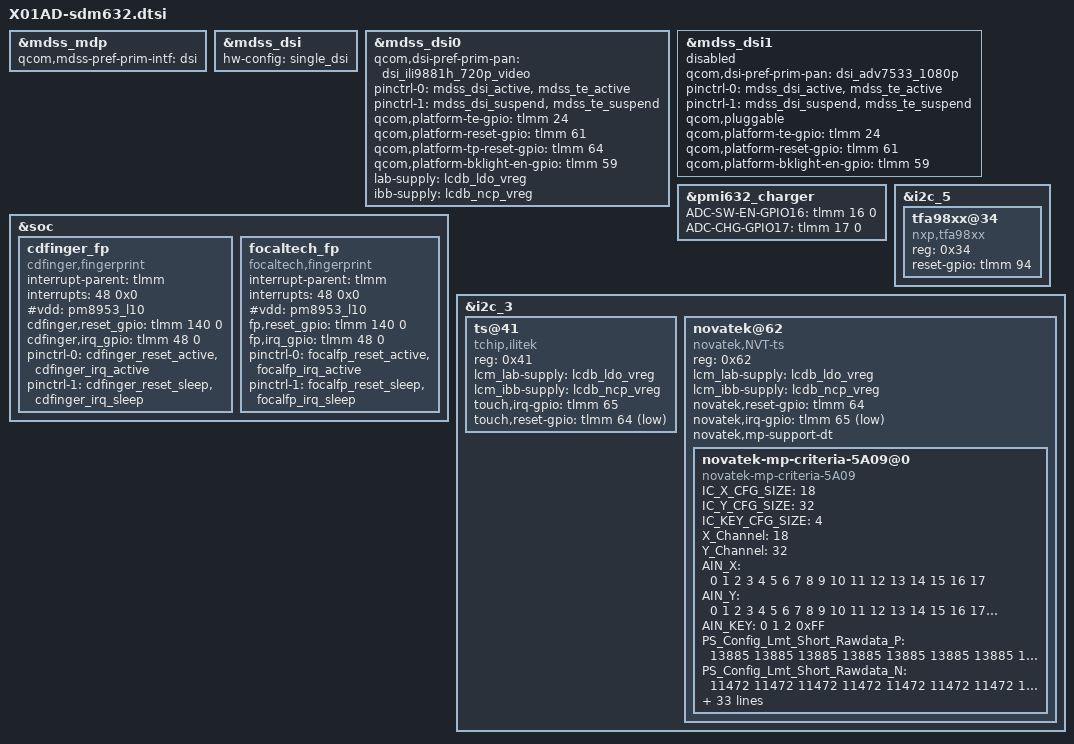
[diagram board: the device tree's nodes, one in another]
/*
 * Copyright (c) 2018, The Linux Foundation. All rights reserved.
 *
 * This program is free software; you can redistribute it and/or modify
 * it under the terms of the GNU General Public License version 2 and
 * only version 2 as published by the Free Software Foundation.
 *
 * This program is distributed in the hope that it will be useful,
 * but WITHOUT ANY WARRANTY; without even the implied warranty of
 * MERCHANTABILITY or FITNESS FOR A PARTICULAR PURPOSE.  See the
 * GNU General Public License for more details.
 */

#include "display/dsi-panel-ili9881h-720p-video.dtsi"
#include "display/dsi-panel-inx6301-720p-video.dtsi"

&mdss_mdp {
	qcom,mdss-pref-prim-intf = "dsi";
};

&mdss_dsi {
	hw-config = "single_dsi";
};

&mdss_dsi0 {
	qcom,dsi-pref-prim-pan = <&dsi_ili9881h_720p_video>;
	pinctrl-names = "mdss_default", "mdss_sleep";
	pinctrl-0 = <&mdss_dsi_active &mdss_te_active>;
	pinctrl-1 = <&mdss_dsi_suspend &mdss_te_suspend>;

	qcom,platform-te-gpio = <&tlmm 24 0>;
	qcom,platform-reset-gpio = <&tlmm 61 0>;
	qcom,platform-tp-reset-gpio = <&tlmm 64 0>;
	qcom,platform-bklight-en-gpio = <&tlmm 59 0>;

	lab-supply = <&lcdb_ldo_vreg>;
	ibb-supply = <&lcdb_ncp_vreg>;
};

&mdss_dsi1 {
	status = "disabled";
	qcom,dsi-pref-prim-pan = <&dsi_adv7533_1080p>;
	pinctrl-names = "mdss_default", "mdss_sleep";
	pinctrl-0 = <&mdss_dsi_active &mdss_te_active>;
	pinctrl-1 = <&mdss_dsi_suspend &mdss_te_suspend>;

	qcom,pluggable;
	qcom,platform-te-gpio = <&tlmm 24 0>;
	qcom,platform-reset-gpio = <&tlmm 61 0>;
	qcom,platform-bklight-en-gpio = <&tlmm 59 0>;
};

&soc {

   cdfinger_fp {
           compatible = "cdfinger,fingerprint";
           interrupt-parent = <&tlmm>;
           interrupts = <48 0x0>;
           #vdd = <&pm8953_l10>;
           cdfinger,reset_gpio = <&tlmm 140 0>;
           cdfinger,irq_gpio = <&tlmm 48 0>;

           pinctrl-names = "cdfinger_active","cdfinger_sleep";
           pinctrl-0 = <&cdfinger_reset_active &cdfinger_irq_active>;
           pinctrl-1 = <&cdfinger_reset_sleep &cdfinger_irq_sleep>;
   };

   focaltech_fp {
           compatible = "focaltech,fingerprint";
           interrupt-parent = <&tlmm>;
           interrupts = <48 0x0>;
           #vdd = <&pm8953_l10>;
           fp,reset_gpio = <&tlmm 140 0>;
           fp,irq_gpio = <&tlmm 48 0>;

           pinctrl-names = "focalfp_active","focalfp_sleep";
           pinctrl-0 = <&focalfp_reset_active &focalfp_irq_active>;
           pinctrl-1 = <&focalfp_reset_sleep &focalfp_irq_sleep>;
   };
};

&pmi632_charger {
       ADC-SW-EN-GPIO16 = <&tlmm 16 0>;
       ADC-CHG-GPIO17 = <&tlmm 17 0>;
};

&i2c_5 {
	status = "okay";
	tfa98xx@34 {
		compatible = "nxp,tfa98xx";
		reg = <0x34>;
		reset-gpio =<&tlmm 94 0>;
	};
};

&i2c_3 {
	status = "ok";
		ts@41 {
		status = "okay";
		compatible = "tchip,ilitek";
		reg = <0x41>;
		lcm_lab-supply = <&lcdb_ldo_vreg>;
		lcm_ibb-supply = <&lcdb_ncp_vreg>;
		touch,irq-gpio = <&tlmm 65 IRQ_TYPE_NONE>;
		touch,reset-gpio = <&tlmm 64 GPIO_ACTIVE_LOW>;
	};
	/* Novatek device tree node */
	novatek@62 {
		compatible = "novatek,NVT-ts";
		reg = <0x62>;
		status = "ok";

		lcm_lab-supply = <&lcdb_ldo_vreg>;
		lcm_ibb-supply = <&lcdb_ncp_vreg>;

		novatek,reset-gpio = <&tlmm 64 0x00>;
		novatek,irq-gpio = <&tlmm 65 0x2001>;

		/* MP */
		novatek,mp-support-dt;

		novatek-mp-criteria-5A09@0 {
			#address-cells = <1>;
			#size-cells = <0>;
			compatible = "novatek-mp-criteria-5A09";

			/* MP Config */
			IC_X_CFG_SIZE = <18>;
			IC_Y_CFG_SIZE = <32>;
			IC_KEY_CFG_SIZE = <4>;
			X_Channel = <18>;
			Y_Channel = <32>;
			AIN_X = <0 1 2 3 4 5 6 7 8 9 10 11 12 13 14 15 16 17>;
			AIN_Y = <0 1 2 3 4 5 6 7 8 9 10 11 12 13 14 15 16
								17 18 19 20 21 22 23 24 25 26 27 28 29 30 31>;
			AIN_KEY = <0 1 2 0xFF>;

			/* MP Criteria */
			PS_Config_Lmt_Short_Rawdata_P = <
				13885 13885 13885 13885 13885 13885 13885 13885 13885 13885 13885 13885 13885 13885 13885 13885 13885 13885
				13885 13885 13885 13885 13885 13885 13885 13885 13885 13885 13885 13885 13885 13885 13885 13885 13885 13885
				13885 13885 13885 13885 13885 13885 13885 13885 13885 13885 13885 13885 13885 13885 13885 13885 13885 13885
				13885 13885 13885 13885 13885 13885 13885 13885 13885 13885 13885 13885 13885 13885 13885 13885 13885 13885
				13885 13885 13885 13885 13885 13885 13885 13885 13885 13885 13885 13885 13885 13885 13885 13885 13885 13885
				13885 13885 13885 13885 13885 13885 13885 13885 13885 13885 13885 13885 13885 13885 13885 13885 13885 13885
				13885 13885 13885 13885 13885 13885 13885 13885 13885 13885 13885 13885 13885 13885 13885 13885 13885 13885
				13885 13885 13885 13885 13885 13885 13885 13885 13885 13885 13885 13885 13885 13885 13885 13885 13885 13885
				13885 13885 13885 13885 13885 13885 13885 13885 13885 13885 13885 13885 13885 13885 13885 13885 13885 13885
				13885 13885 13885 13885 13885 13885 13885 13885 13885 13885 13885 13885 13885 13885 13885 13885 13885 13885
				13885 13885 13885 13885 13885 13885 13885 13885 13885 13885 13885 13885 13885 13885 13885 13885 13885 13885
				13885 13885 13885 13885 13885 13885 13885 13885 13885 13885 13885 13885 13885 13885 13885 13885 13885 13885
				13885 13885 13885 13885 13885 13885 13885 13885 13885 13885 13885 13885 13885 13885 13885 13885 13885 13885
				13885 13885 13885 13885 13885 13885 13885 13885 13885 13885 13885 13885 13885 13885 13885 13885 13885 13885
				13885 13885 13885 13885 13885 13885 13885 13885 13885 13885 13885 13885 13885 13885 13885 13885 13885 13885
				13885 13885 13885 13885 13885 13885 13885 13885 13885 13885 13885 13885 13885 13885 13885 13885 13885 13885
				13885 13885 13885 13885 13885 13885 13885 13885 13885 13885 13885 13885 13885 13885 13885 13885 13885 13885
				13885 13885 13885 13885 13885 13885 13885 13885 13885 13885 13885 13885 13885 13885 13885 13885 13885 13885
				13885 13885 13885 13885 13885 13885 13885 13885 13885 13885 13885 13885 13885 13885 13885 13885 13885 13885
				13885 13885 13885 13885 13885 13885 13885 13885 13885 13885 13885 13885 13885 13885 13885 13885 13885 13885
				13885 13885 13885 13885 13885 13885 13885 13885 13885 13885 13885 13885 13885 13885 13885 13885 13885 13885
				13885 13885 13885 13885 13885 13885 13885 13885 13885 13885 13885 13885 13885 13885 13885 13885 13885 13885
				13885 13885 13885 13885 13885 13885 13885 13885 13885 13885 13885 13885 13885 13885 13885 13885 13885 13885
				13885 13885 13885 13885 13885 13885 13885 13885 13885 13885 13885 13885 13885 13885 13885 13885 13885 13885
				13885 13885 13885 13885 13885 13885 13885 13885 13885 13885 13885 13885 13885 13885 13885 13885 13885 13885
				13885 13885 13885 13885 13885 13885 13885 13885 13885 13885 13885 13885 13885 13885 13885 13885 13885 13885
				13885 13885 13885 13885 13885 13885 13885 13885 13885 13885 13885 13885 13885 13885 13885 13885 13885 13885
				13885 13885 13885 13885 13885 13885 13885 13885 13885 13885 13885 13885 13885 13885 13885 13885 13885 13885
				13885 13885 13885 13885 13885 13885 13885 13885 13885 13885 13885 13885 13885 13885 13885 13885 13885 13885
				13885 13885 13885 13885 13885 13885 13885 13885 13885 13885 13885 13885 13885 13885 13885 13885 13885 13885
				13885 13885 13885 13885 13885 13885 13885 13885 13885 13885 13885 13885 13885 13885 13885 13885 13885 13885
				13885 13885 13885 13885 13885 13885 13885 13885 13885 13885 13885 13885 13885 13885 13885 13885 13885 13885
				13885 13885 13885>;

			PS_Config_Lmt_Short_Rawdata_N = <
				11472 11472 11472 11472 11472 11472 11472 11472 11472 11472 11472 11472 11472 11472 11472 11472 11472 11472
				11472 11472 11472 11472 11472 11472 11472 11472 11472 11472 11472 11472 11472 11472 11472 11472 11472 11472
				11472 11472 11472 11472 11472 11472 11472 11472 11472 11472 11472 11472 11472 11472 11472 11472 11472 11472
				11472 11472 11472 11472 11472 11472 11472 11472 11472 11472 11472 11472 11472 11472 11472 11472 11472 11472
				11472 11472 11472 11472 11472 11472 11472 11472 11472 11472 11472 11472 11472 11472 11472 11472 11472 11472
				11472 11472 11472 11472 11472 11472 11472 11472 11472 11472 11472 11472 11472 11472 11472 11472 11472 11472
				11472 11472 11472 11472 11472 11472 11472 11472 11472 11472 11472 11472 11472 11472 11472 11472 11472 11472
				11472 11472 11472 11472 11472 11472 11472 11472 11472 11472 11472 11472 11472 11472 11472 11472 11472 11472
				11472 11472 11472 11472 11472 11472 11472 11472 11472 11472 11472 11472 11472 11472 11472 11472 11472 11472
				11472 11472 11472 11472 11472 11472 11472 11472 11472 11472 11472 11472 11472 11472 11472 11472 11472 11472
				11472 11472 11472 11472 11472 11472 11472 11472 11472 11472 11472 11472 11472 11472 11472 11472 11472 11472
				11472 11472 11472 11472 11472 11472 11472 11472 11472 11472 11472 11472 11472 11472 11472 11472 11472 11472
				11472 11472 11472 11472 11472 11472 11472 11472 11472 11472 11472 11472 11472 11472 11472 11472 11472 11472
				11472 11472 11472 11472 11472 11472 11472 11472 11472 11472 11472 11472 11472 11472 11472 11472 11472 11472
				11472 11472 11472 11472 11472 11472 11472 11472 11472 11472 11472 11472 11472 11472 11472 11472 11472 11472
				11472 11472 11472 11472 11472 11472 11472 11472 11472 11472 11472 11472 11472 11472 11472 11472 11472 11472
				11472 11472 11472 11472 11472 11472 11472 11472 11472 11472 11472 11472 11472 11472 11472 11472 11472 11472
				11472 11472 11472 11472 11472 11472 11472 11472 11472 11472 11472 11472 11472 11472 11472 11472 11472 11472
				11472 11472 11472 11472 11472 11472 11472 11472 11472 11472 11472 11472 11472 11472 11472 11472 11472 11472
				11472 11472 11472 11472 11472 11472 11472 11472 11472 11472 11472 11472 11472 11472 11472 11472 11472 11472
				11472 11472 11472 11472 11472 11472 11472 11472 11472 11472 11472 11472 11472 11472 11472 11472 11472 11472
				11472 11472 11472 11472 11472 11472 11472 11472 11472 11472 11472 11472 11472 11472 11472 11472 11472 11472
				11472 11472 11472 11472 11472 11472 11472 11472 11472 11472 11472 11472 11472 11472 11472 11472 11472 11472
				11472 11472 11472 11472 11472 11472 11472 11472 11472 11472 11472 11472 11472 11472 11472 11472 11472 11472
				11472 11472 11472 11472 11472 11472 11472 11472 11472 11472 11472 11472 11472 11472 11472 11472 11472 11472
				11472 11472 11472 11472 11472 11472 11472 11472 11472 11472 11472 11472 11472 11472 11472 11472 11472 11472
				11472 11472 11472 11472 11472 11472 11472 11472 11472 11472 11472 11472 11472 11472 11472 11472 11472 11472
				11472 11472 11472 11472 11472 11472 11472 11472 11472 11472 11472 11472 11472 11472 11472 11472 11472 11472
				11472 11472 11472 11472 11472 11472 11472 11472 11472 11472 11472 11472 11472 11472 11472 11472 11472 11472
				11472 11472 11472 11472 11472 11472 11472 11472 11472 11472 11472 11472 11472 11472 11472 11472 11472 11472
				11472 11472 11472 11472 11472 11472 11472 11472 11472 11472 11472 11472 11472 11472 11472 11472 11472 11472
				11472 11472 11472 11472 11472 11472 11472 11472 11472 11472 11472 11472 11472 11472 11472 11472 11472 11472
				11472 11472 11472>;

			PS_Config_Lmt_Short_Diff_P = <
				6300 6300 6300 6300 6300 6300 6300 6300 6300 6300 6300 6300 6300 6300 6300 6300 6300 6300
				6300 6300 6300 6300 6300 6300 6300 6300 6300 6300 6300 6300 6300 6300 6300 6300 6300 6300
				6300 6300 6300 6300 6300 6300 6300 6300 6300 6300 6300 6300 6300 6300 6300 6300 6300 6300
				6300 6300 6300 6300 6300 6300 6300 6300 6300 6300 6300 6300 6300 6300 6300 6300 6300 6300
				6300 6300 6300 6300 6300 6300 6300 6300 6300 6300 6300 6300 6300 6300 6300 6300 6300 6300
				6300 6300 6300 6300 6300 6300 6300 6300 6300 6300 6300 6300 6300 6300 6300 6300 6300 6300
				6300 6300 6300 6300 6300 6300 6300 6300 6300 6300 6300 6300 6300 6300 6300 6300 6300 6300
				6300 6300 6300 6300 6300 6300 6300 6300 6300 6300 6300 6300 6300 6300 6300 6300 6300 6300
				6300 6300 6300 6300 6300 6300 6300 6300 6300 6300 6300 6300 6300 6300 6300 6300 6300 6300
				6300 6300 6300 6300 6300 6300 6300 6300 6300 6300 6300 6300 6300 6300 6300 6300 6300 6300
				6300 6300 6300 6300 6300 6300 6300 6300 6300 6300 6300 6300 6300 6300 6300 6300 6300 6300
				6300 6300 6300 6300 6300 6300 6300 6300 6300 6300 6300 6300 6300 6300 6300 6300 6300 6300
				6300 6300 6300 6300 6300 6300 6300 6300 6300 6300 6300 6300 6300 6300 6300 6300 6300 6300
				6300 6300 6300 6300 6300 6300 6300 6300 6300 6300 6300 6300 6300 6300 6300 6300 6300 6300
				6300 6300 6300 6300 6300 6300 6300 6300 6300 6300 6300 6300 6300 6300 6300 6300 6300 6300
				6300 6300 6300 6300 6300 6300 6300 6300 6300 6300 6300 6300 6300 6300 6300 6300 6300 6300
				6300 6300 6300 6300 6300 6300 6300 6300 6300 6300 6300 6300 6300 6300 6300 6300 6300 6300
				6300 6300 6300 6300 6300 6300 6300 6300 6300 6300 6300 6300 6300 6300 6300 6300 6300 6300
				6300 6300 6300 6300 6300 6300 6300 6300 6300 6300 6300 6300 6300 6300 6300 6300 6300 6300
				6300 6300 6300 6300 6300 6300 6300 6300 6300 6300 6300 6300 6300 6300 6300 6300 6300 6300
				6300 6300 6300 6300 6300 6300 6300 6300 6300 6300 6300 6300 6300 6300 6300 6300 6300 6300
				6300 6300 6300 6300 6300 6300 6300 6300 6300 6300 6300 6300 6300 6300 6300 6300 6300 6300
				6300 6300 6300 6300 6300 6300 6300 6300 6300 6300 6300 6300 6300 6300 6300 6300 6300 6300
				6300 6300 6300 6300 6300 6300 6300 6300 6300 6300 6300 6300 6300 6300 6300 6300 6300 6300
				6300 6300 6300 6300 6300 6300 6300 6300 6300 6300 6300 6300 6300 6300 6300 6300 6300 6300
				6300 6300 6300 6300 6300 6300 6300 6300 6300 6300 6300 6300 6300 6300 6300 6300 6300 6300
				6300 6300 6300 6300 6300 6300 6300 6300 6300 6300 6300 6300 6300 6300 6300 6300 6300 6300
				6300 6300 6300 6300 6300 6300 6300 6300 6300 6300 6300 6300 6300 6300 6300 6300 6300 6300
				6300 6300 6300 6300 6300 6300 6300 6300 6300 6300 6300 6300 6300 6300 6300 6300 6300 6300
				6300 6300 6300 6300 6300 6300 6300 6300 6300 6300 6300 6300 6300 6300 6300 6300 6300 6300
				6300 6300 6300 6300 6300 6300 6300 6300 6300 6300 6300 6300 6300 6300 6300 6300 6300 6300
				6300 6300 6300 6300 6300 6300 6300 6300 6300 6300 6300 6300 6300 6300 6300 6300 6300 6300
				6300 6300 6300>;

			PS_Config_Lmt_Short_Diff_N = <
				0 0 0 0 0 0 0 0 0 0 0 0 0 0 0 0 0 0
				0 0 0 0 0 0 0 0 0 0 0 0 0 0 0 0 0 0
				0 0 0 0 0 0 0 0 0 0 0 0 0 0 0 0 0 0
				0 0 0 0 0 0 0 0 0 0 0 0 0 0 0 0 0 0
				0 0 0 0 0 0 0 0 0 0 0 0 0 0 0 0 0 0
				0 0 0 0 0 0 0 0 0 0 0 0 0 0 0 0 0 0
				0 0 0 0 0 0 0 0 0 0 0 0 0 0 0 0 0 0
				0 0 0 0 0 0 0 0 0 0 0 0 0 0 0 0 0 0
				0 0 0 0 0 0 0 0 0 0 0 0 0 0 0 0 0 0
				0 0 0 0 0 0 0 0 0 0 0 0 0 0 0 0 0 0
				0 0 0 0 0 0 0 0 0 0 0 0 0 0 0 0 0 0
				0 0 0 0 0 0 0 0 0 0 0 0 0 0 0 0 0 0
				0 0 0 0 0 0 0 0 0 0 0 0 0 0 0 0 0 0
				0 0 0 0 0 0 0 0 0 0 0 0 0 0 0 0 0 0
				0 0 0 0 0 0 0 0 0 0 0 0 0 0 0 0 0 0
				0 0 0 0 0 0 0 0 0 0 0 0 0 0 0 0 0 0
				0 0 0 0 0 0 0 0 0 0 0 0 0 0 0 0 0 0
				0 0 0 0 0 0 0 0 0 0 0 0 0 0 0 0 0 0
				0 0 0 0 0 0 0 0 0 0 0 0 0 0 0 0 0 0
				0 0 0 0 0 0 0 0 0 0 0 0 0 0 0 0 0 0
				0 0 0 0 0 0 0 0 0 0 0 0 0 0 0 0 0 0
				0 0 0 0 0 0 0 0 0 0 0 0 0 0 0 0 0 0
				0 0 0 0 0 0 0 0 0 0 0 0 0 0 0 0 0 0
				0 0 0 0 0 0 0 0 0 0 0 0 0 0 0 0 0 0
				0 0 0 0 0 0 0 0 0 0 0 0 0 0 0 0 0 0
				0 0 0 0 0 0 0 0 0 0 0 0 0 0 0 0 0 0
				0 0 0 0 0 0 0 0 0 0 0 0 0 0 0 0 0 0
				0 0 0 0 0 0 0 0 0 0 0 0 0 0 0 0 0 0
				0 0 0 0 0 0 0 0 0 0 0 0 0 0 0 0 0 0
				0 0 0 0 0 0 0 0 0 0 0 0 0 0 0 0 0 0
				0 0 0 0 0 0 0 0 0 0 0 0 0 0 0 0 0 0
				0 0 0 0 0 0 0 0 0 0 0 0 0 0 0 0 0 0
				0 0 0>;

			PS_Config_Lmt_Short_Base_P = <
				2000 2000 2000 2000 2000 2000 2000 2000 2000 2000 2000 2000 2000 2000 2000 2000 2000 2000
				2000 2000 2000 2000 2000 2000 2000 2000 2000 2000 2000 2000 2000 2000 2000 2000 2000 2000
				2000 2000 2000 2000 2000 2000 2000 2000 2000 2000 2000 2000 2000 2000 2000 2000 2000 2000
				2000 2000 2000 2000 2000 2000 2000 2000 2000 2000 2000 2000 2000 2000 2000 2000 2000 2000
				2000 2000 2000 2000 2000 2000 2000 2000 2000 2000 2000 2000 2000 2000 2000 2000 2000 2000
				2000 2000 2000 2000 2000 2000 2000 2000 2000 2000 2000 2000 2000 2000 2000 2000 2000 2000
				2000 2000 2000 2000 2000 2000 2000 2000 2000 2000 2000 2000 2000 2000 2000 2000 2000 2000
				2000 2000 2000 2000 2000 2000 2000 2000 2000 2000 2000 2000 2000 2000 2000 2000 2000 2000
				2000 2000 2000 2000 2000 2000 2000 2000 2000 2000 2000 2000 2000 2000 2000 2000 2000 2000
				2000 2000 2000 2000 2000 2000 2000 2000 2000 2000 2000 2000 2000 2000 2000 2000 2000 2000
				2000 2000 2000 2000 2000 2000 2000 2000 2000 2000 2000 2000 2000 2000 2000 2000 2000 2000
				2000 2000 2000 2000 2000 2000 2000 2000 2000 2000 2000 2000 2000 2000 2000 2000 2000 2000
				2000 2000 2000 2000 2000 2000 2000 2000 2000 2000 2000 2000 2000 2000 2000 2000 2000 2000
				2000 2000 2000 2000 2000 2000 2000 2000 2000 2000 2000 2000 2000 2000 2000 2000 2000 2000
				2000 2000 2000 2000 2000 2000 2000 2000 2000 2000 2000 2000 2000 2000 2000 2000 2000 2000
				2000 2000 2000 2000 2000 2000 2000 2000 2000 2000 2000 2000 2000 2000 2000 2000 2000 2000
				2000 2000 2000 2000 2000 2000 2000 2000 2000 2000 2000 2000 2000 2000 2000 2000 2000 2000
				2000 2000 2000 2000 2000 2000 2000 2000 2000 2000 2000 2000 2000 2000 2000 2000 2000 2000
				2000 2000 2000 2000 2000 2000 2000 2000 2000 2000 2000 2000 2000 2000 2000 2000 2000 2000
				2000 2000 2000 2000 2000 2000 2000 2000 2000 2000 2000 2000 2000 2000 2000 2000 2000 2000
				2000 2000 2000 2000 2000 2000 2000 2000 2000 2000 2000 2000 2000 2000 2000 2000 2000 2000
				2000 2000 2000 2000 2000 2000 2000 2000 2000 2000 2000 2000 2000 2000 2000 2000 2000 2000
				2000 2000 2000 2000 2000 2000 2000 2000 2000 2000 2000 2000 2000 2000 2000 2000 2000 2000
				2000 2000 2000 2000 2000 2000 2000 2000 2000 2000 2000 2000 2000 2000 2000 2000 2000 2000
				2000 2000 2000 2000 2000 2000 2000 2000 2000 2000 2000 2000 2000 2000 2000 2000 2000 2000
				2000 2000 2000 2000 2000 2000 2000 2000 2000 2000 2000 2000 2000 2000 2000 2000 2000 2000
				2000 2000 2000 2000 2000 2000 2000 2000 2000 2000 2000 2000 2000 2000 2000 2000 2000 2000
				2000 2000 2000 2000 2000 2000 2000 2000 2000 2000 2000 2000 2000 2000 2000 2000 2000 2000
				2000 2000 2000 2000 2000 2000 2000 2000 2000 2000 2000 2000 2000 2000 2000 2000 2000 2000
				2000 2000 2000 2000 2000 2000 2000 2000 2000 2000 2000 2000 2000 2000 2000 2000 2000 2000
				2000 2000 2000 2000 2000 2000 2000 2000 2000 2000 2000 2000 2000 2000 2000 2000 2000 2000
				2000 2000 2000 2000 2000 2000 2000 2000 2000 2000 2000 2000 2000 2000 2000 2000 2000 2000
				2000 2000 2000>;

			PS_Config_Lmt_Short_Base_N = <
				(-2000) (-2000) (-2000) (-2000) (-2000) (-2000) (-2000) (-2000) (-2000) (-2000) (-2000) (-2000) (-2000) (-2000) (-2000) (-2000) (-2000) (-2000)
				(-2000) (-2000) (-2000) (-2000) (-2000) (-2000) (-2000) (-2000) (-2000) (-2000) (-2000) (-2000) (-2000) (-2000) (-2000) (-2000) (-2000) (-2000)
				(-2000) (-2000) (-2000) (-2000) (-2000) (-2000) (-2000) (-2000) (-2000) (-2000) (-2000) (-2000) (-2000) (-2000) (-2000) (-2000) (-2000) (-2000)
				(-2000) (-2000) (-2000) (-2000) (-2000) (-2000) (-2000) (-2000) (-2000) (-2000) (-2000) (-2000) (-2000) (-2000) (-2000) (-2000) (-2000) (-2000)
				(-2000) (-2000) (-2000) (-2000) (-2000) (-2000) (-2000) (-2000) (-2000) (-2000) (-2000) (-2000) (-2000) (-2000) (-2000) (-2000) (-2000) (-2000)
				(-2000) (-2000) (-2000) (-2000) (-2000) (-2000) (-2000) (-2000) (-2000) (-2000) (-2000) (-2000) (-2000) (-2000) (-2000) (-2000) (-2000) (-2000)
				(-2000) (-2000) (-2000) (-2000) (-2000) (-2000) (-2000) (-2000) (-2000) (-2000) (-2000) (-2000) (-2000) (-2000) (-2000) (-2000) (-2000) (-2000)
				(-2000) (-2000) (-2000) (-2000) (-2000) (-2000) (-2000) (-2000) (-2000) (-2000) (-2000) (-2000) (-2000) (-2000) (-2000) (-2000) (-2000) (-2000)
				(-2000) (-2000) (-2000) (-2000) (-2000) (-2000) (-2000) (-2000) (-2000) (-2000) (-2000) (-2000) (-2000) (-2000) (-2000) (-2000) (-2000) (-2000)
				(-2000) (-2000) (-2000) (-2000) (-2000) (-2000) (-2000) (-2000) (-2000) (-2000) (-2000) (-2000) (-2000) (-2000) (-2000) (-2000) (-2000) (-2000)
				(-2000) (-2000) (-2000) (-2000) (-2000) (-2000) (-2000) (-2000) (-2000) (-2000) (-2000) (-2000) (-2000) (-2000) (-2000) (-2000) (-2000) (-2000)
				(-2000) (-2000) (-2000) (-2000) (-2000) (-2000) (-2000) (-2000) (-2000) (-2000) (-2000) (-2000) (-2000) (-2000) (-2000) (-2000) (-2000) (-2000)
				(-2000) (-2000) (-2000) (-2000) (-2000) (-2000) (-2000) (-2000) (-2000) (-2000) (-2000) (-2000) (-2000) (-2000) (-2000) (-2000) (-2000) (-2000)
				(-2000) (-2000) (-2000) (-2000) (-2000) (-2000) (-2000) (-2000) (-2000) (-2000) (-2000) (-2000) (-2000) (-2000) (-2000) (-2000) (-2000) (-2000)
				(-2000) (-2000) (-2000) (-2000) (-2000) (-2000) (-2000) (-2000) (-2000) (-2000) (-2000) (-2000) (-2000) (-2000) (-2000) (-2000) (-2000) (-2000)
				(-2000) (-2000) (-2000) (-2000) (-2000) (-2000) (-2000) (-2000) (-2000) (-2000) (-2000) (-2000) (-2000) (-2000) (-2000) (-2000) (-2000) (-2000)
				(-2000) (-2000) (-2000) (-2000) (-2000) (-2000) (-2000) (-2000) (-2000) (-2000) (-2000) (-2000) (-2000) (-2000) (-2000) (-2000) (-2000) (-2000)
				(-2000) (-2000) (-2000) (-2000) (-2000) (-2000) (-2000) (-2000) (-2000) (-2000) (-2000) (-2000) (-2000) (-2000) (-2000) (-2000) (-2000) (-2000)
				(-2000) (-2000) (-2000) (-2000) (-2000) (-2000) (-2000) (-2000) (-2000) (-2000) (-2000) (-2000) (-2000) (-2000) (-2000) (-2000) (-2000) (-2000)
				(-2000) (-2000) (-2000) (-2000) (-2000) (-2000) (-2000) (-2000) (-2000) (-2000) (-2000) (-2000) (-2000) (-2000) (-2000) (-2000) (-2000) (-2000)
				(-2000) (-2000) (-2000) (-2000) (-2000) (-2000) (-2000) (-2000) (-2000) (-2000) (-2000) (-2000) (-2000) (-2000) (-2000) (-2000) (-2000) (-2000)
				(-2000) (-2000) (-2000) (-2000) (-2000) (-2000) (-2000) (-2000) (-2000) (-2000) (-2000) (-2000) (-2000) (-2000) (-2000) (-2000) (-2000) (-2000)
				(-2000) (-2000) (-2000) (-2000) (-2000) (-2000) (-2000) (-2000) (-2000) (-2000) (-2000) (-2000) (-2000) (-2000) (-2000) (-2000) (-2000) (-2000)
				(-2000) (-2000) (-2000) (-2000) (-2000) (-2000) (-2000) (-2000) (-2000) (-2000) (-2000) (-2000) (-2000) (-2000) (-2000) (-2000) (-2000) (-2000)
				(-2000) (-2000) (-2000) (-2000) (-2000) (-2000) (-2000) (-2000) (-2000) (-2000) (-2000) (-2000) (-2000) (-2000) (-2000) (-2000) (-2000) (-2000)
				(-2000) (-2000) (-2000) (-2000) (-2000) (-2000) (-2000) (-2000) (-2000) (-2000) (-2000) (-2000) (-2000) (-2000) (-2000) (-2000) (-2000) (-2000)
				(-2000) (-2000) (-2000) (-2000) (-2000) (-2000) (-2000) (-2000) (-2000) (-2000) (-2000) (-2000) (-2000) (-2000) (-2000) (-2000) (-2000) (-2000)
				(-2000) (-2000) (-2000) (-2000) (-2000) (-2000) (-2000) (-2000) (-2000) (-2000) (-2000) (-2000) (-2000) (-2000) (-2000) (-2000) (-2000) (-2000)
				(-2000) (-2000) (-2000) (-2000) (-2000) (-2000) (-2000) (-2000) (-2000) (-2000) (-2000) (-2000) (-2000) (-2000) (-2000) (-2000) (-2000) (-2000)
				(-2000) (-2000) (-2000) (-2000) (-2000) (-2000) (-2000) (-2000) (-2000) (-2000) (-2000) (-2000) (-2000) (-2000) (-2000) (-2000) (-2000) (-2000)
				(-2000) (-2000) (-2000) (-2000) (-2000) (-2000) (-2000) (-2000) (-2000) (-2000) (-2000) (-2000) (-2000) (-2000) (-2000) (-2000) (-2000) (-2000)
				(-2000) (-2000) (-2000) (-2000) (-2000) (-2000) (-2000) (-2000) (-2000) (-2000) (-2000) (-2000) (-2000) (-2000) (-2000) (-2000) (-2000) (-2000)
				(-2000) (-2000) (-2000)>;

			PS_Config_Lmt_Open_Rawdata_P = <
				65535 3362 3080 3095 2976 2970 65535 65535 65535 65535 65535 65535 2995 2988 3102 3065 3292 65535
				1606 1599 1595 1592 1534 1578 1586 1567 1517 1544 1611 1632 1615 1578 1637 1639 1608 1629
				1611 1584 1584 1584 1586 1576 1586 1586 1581 1552 1566 1565 1556 1565 1560 1562 1532 1577
				1574 1548 1543 1543 1544 1536 1544 1541 1547 1555 1566 1562 1549 1562 1556 1560 1528 1574
				1658 1632 1633 1630 1628 1618 1628 1629 1630 1618 1628 1623 1612 1626 1617 1619 1585 1636
				1640 1607 1606 1610 1604 1595 1608 1604 1603 1604 1614 1612 1602 1611 1610 1611 1574 1625
				1637 1606 1602 1602 1600 1589 1599 1600 1602 1597 1606 1606 1591 1607 1604 1607 1569 1622
				1597 1570 1569 1566 1565 1556 1562 1560 1559 1599 1610 1608 1593 1608 1608 1611 1577 1625
				1695 1667 1662 1662 1659 1648 1660 1658 1656 1595 1602 1602 1589 1610 1608 1604 1573 1625
				1655 1621 1625 1618 1614 1606 1614 1612 1611 1633 1643 1641 1626 1647 1645 1649 1612 1663
				1628 1595 1592 1588 1585 1571 1582 1584 1581 1548 1556 1554 1545 1563 1560 1566 1533 1585
				1647 1610 1604 1600 1595 1584 1596 1595 1593 1604 1614 1610 1603 1619 1619 1623 1585 1637
				1688 1649 1648 1643 1644 1632 1641 1643 1640 1599 1610 1608 1599 1614 1611 1622 1582 1636
				1656 1622 1617 1614 1607 1599 1607 1610 1608 1666 1678 1678 1666 1684 1682 1691 1652 1707
				1680 1644 1639 1634 1632 1622 1633 1632 1630 1636 1644 1641 1630 1647 1645 1649 1619 1676
				1640 1602 1600 1597 1595 1582 1593 1596 1593 1629 1639 1637 1623 1643 1643 1647 1610 1667
				1692 1654 1658 1652 1656 1645 1656 1654 1655 1596 1607 1604 1593 1608 1607 1618 1578 1637
				1660 1629 1622 1617 1617 1610 1621 1618 1622 1660 1671 1670 1659 1673 1671 1684 1644 1702
				1692 1662 1651 1651 1651 1640 1652 1649 1651 1686 1699 1697 1682 1702 1707 1708 1682 1733
				1722 1692 1692 1695 1684 1666 1678 1677 1677 1658 1670 1671 1655 1670 1691 1688 1659 1711
				1678 1648 1652 1647 1637 1619 1629 1628 1629 1615 1623 1625 1610 1633 1643 1655 1618 1662
				1685 1651 1659 1648 1655 1625 1634 1633 1634 1615 1626 1625 1607 1644 1644 1654 1615 1666
				1702 1667 1673 1662 1670 1643 1652 1649 1647 1648 1656 1654 1637 1680 1678 1686 1645 1697
				1737 1704 1708 1703 1710 1680 1688 1688 1686 1634 1643 1644 1626 1667 1665 1671 1634 1688
				1678 1644 1649 1645 1649 1615 1629 1625 1623 1628 1637 1636 1622 1662 1658 1666 1633 1680
				1670 1634 1639 1633 1639 1606 1615 1614 1612 1641 1648 1652 1634 1673 1674 1684 1644 1697
				1686 1652 1658 1649 1651 1615 1630 1628 1628 1647 1658 1659 1641 1684 1684 1689 1655 1710
				1691 1658 1656 1649 1651 1617 1633 1626 1629 1596 1602 1604 1584 1626 1628 1634 1602 1658
				1643 1610 1607 1597 1600 1566 1581 1580 1577 1573 1580 1581 1562 1603 1600 1615 1578 1630
				1649 1612 1615 1610 1608 1573 1589 1584 1584 1569 1576 1578 1560 1597 1603 1612 1576 1634
				1607 1596 1599 1593 1595 1562 1576 1566 1571 1596 1599 1603 1585 1629 1629 1634 1600 1630
				1278 1588 1589 1582 1584 1548 1563 1559 1560 1552 1558 1560 1540 1582 1582 1592 1556 1266
				2000 2000 2000>;

			PS_Config_Lmt_Open_Rawdata_N = <
				0 1546 1416 1423 1368 1366 0 0 0 0 0 0 1377 1374 1426 1409 1514 0
				738 735 733 732 706 726 730 721 697 710 741 750 743 726 753 753 740 749
				741 728 728 728 730 725 730 730 727 714 720 719 716 719 718 718 704 725
				724 712 709 709 710 706 710 709 711 715 720 718 713 718 716 718 702 724
				762 750 751 750 748 744 748 749 750 744 748 747 742 748 743 745 729 752
				754 739 738 740 738 733 740 738 737 738 742 742 736 741 740 741 724 747
				753 738 736 736 736 731 735 736 736 735 738 738 731 739 738 739 721 746
				735 722 721 720 719 716 718 718 717 735 740 740 733 740 740 741 725 747
				779 767 764 764 763 758 764 762 762 733 736 736 731 740 740 738 723 747
				761 745 747 744 742 738 742 742 741 751 755 755 748 757 757 759 742 765
				748 733 732 730 729 723 728 728 727 712 716 714 711 719 718 720 705 729
				757 740 738 736 733 728 734 733 733 738 742 740 737 745 745 747 729 753
				776 759 758 755 756 750 755 755 754 735 740 740 735 742 741 746 728 752
				762 746 743 742 739 735 739 740 740 766 772 772 766 774 774 777 760 785
				772 756 753 752 750 746 751 750 750 752 756 755 750 757 757 759 745 770
				754 736 736 735 733 728 733 734 733 749 753 753 747 755 755 757 740 767
				778 760 762 760 762 757 762 760 761 734 739 738 733 740 739 744 726 753
				764 749 746 743 743 740 745 744 746 764 769 768 763 769 769 774 756 782
				778 764 759 759 759 754 760 759 759 776 781 781 774 782 785 786 774 797
				792 778 778 779 774 766 772 771 771 762 768 769 761 768 777 776 763 787
				772 758 760 757 753 745 749 748 749 743 747 747 740 751 755 761 744 764
				775 759 763 758 761 747 752 751 752 743 748 747 739 756 756 760 743 766
				782 767 769 764 768 755 760 759 757 758 762 760 753 772 772 776 757 781
				799 784 786 783 786 772 776 776 776 752 755 756 748 767 765 769 752 776
				772 756 759 757 759 743 749 747 747 748 753 752 746 764 762 766 751 772
				768 752 753 751 753 738 743 742 742 755 758 760 752 769 770 774 756 781
				776 760 762 759 759 743 750 748 748 757 762 763 755 774 774 777 761 786
				777 762 762 759 759 743 751 748 749 734 736 738 728 748 748 752 736 762
				755 740 739 735 736 720 727 726 725 723 726 727 718 737 736 743 726 750
				759 742 743 740 740 723 731 728 728 721 725 726 718 735 737 742 725 752
				739 734 735 733 733 718 725 720 723 734 735 737 729 749 749 752 736 750
				588 730 731 728 728 712 719 717 718 714 716 718 708 728 728 732 716 582
				650 650 650>;

			PS_Config_Lmt_FW_Rawdata_P = <
				65535 1600 1600 1600 1600 1600 65535 65535 65535 65535 65535 65535 1600 1600 1600 1600 1600 65535
				1600 1600 1600 1600 1600 1600 1600 1600 1600 1600 1600 1600 1600 1600 1600 1600 1600 1600
				1600 1600 1600 1600 1600 1600 1600 1600 1600 1600 1600 1600 1600 1600 1600 1600 1600 1600
				1600 1600 1600 1600 1600 1600 1600 1600 1600 1600 1600 1600 1600 1600 1600 1600 1600 1600
				1600 1600 1600 1600 1600 1600 1600 1600 1600 1600 1600 1600 1600 1600 1600 1600 1600 1600
				1600 1600 1600 1600 1600 1600 1600 1600 1600 1600 1600 1600 1600 1600 1600 1600 1600 1600
				1600 1600 1600 1600 1600 1600 1600 1600 1600 1600 1600 1600 1600 1600 1600 1600 1600 1600
				1600 1600 1600 1600 1600 1600 1600 1600 1600 1600 1600 1600 1600 1600 1600 1600 1600 1600
				1600 1600 1600 1600 1600 1600 1600 1600 1600 1600 1600 1600 1600 1600 1600 1600 1600 1600
				1600 1600 1600 1600 1600 1600 1600 1600 1600 1600 1600 1600 1600 1600 1600 1600 1600 1600
				1600 1600 1600 1600 1600 1600 1600 1600 1600 1600 1600 1600 1600 1600 1600 1600 1600 1600
				1600 1600 1600 1600 1600 1600 1600 1600 1600 1600 1600 1600 1600 1600 1600 1600 1600 1600
				1600 1600 1600 1600 1600 1600 1600 1600 1600 1600 1600 1600 1600 1600 1600 1600 1600 1600
				1600 1600 1600 1600 1600 1600 1600 1600 1600 1600 1600 1600 1600 1600 1600 1600 1600 1600
				1600 1600 1600 1600 1600 1600 1600 1600 1600 1600 1600 1600 1600 1600 1600 1600 1600 1600
				1600 1600 1600 1600 1600 1600 1600 1600 1600 1600 1600 1600 1600 1600 1600 1600 1600 1600
				1600 1600 1600 1600 1600 1600 1600 1600 1600 1600 1600 1600 1600 1600 1600 1600 1600 1600
				1600 1600 1600 1600 1600 1600 1600 1600 1600 1600 1600 1600 1600 1600 1600 1600 1600 1600
				1600 1600 1600 1600 1600 1600 1600 1600 1600 1600 1600 1600 1600 1600 1600 1600 1600 1600
				1600 1600 1600 1600 1600 1600 1600 1600 1600 1600 1600 1600 1600 1600 1600 1600 1600 1600
				1600 1600 1600 1600 1600 1600 1600 1600 1600 1600 1600 1600 1600 1600 1600 1600 1600 1600
				1600 1600 1600 1600 1600 1600 1600 1600 1600 1600 1600 1600 1600 1600 1600 1600 1600 1600
				1600 1600 1600 1600 1600 1600 1600 1600 1600 1600 1600 1600 1600 1600 1600 1600 1600 1600
				1600 1600 1600 1600 1600 1600 1600 1600 1600 1600 1600 1600 1600 1600 1600 1600 1600 1600
				1600 1600 1600 1600 1600 1600 1600 1600 1600 1600 1600 1600 1600 1600 1600 1600 1600 1600
				1600 1600 1600 1600 1600 1600 1600 1600 1600 1600 1600 1600 1600 1600 1600 1600 1600 1600
				1600 1600 1600 1600 1600 1600 1600 1600 1600 1600 1600 1600 1600 1600 1600 1600 1600 1600
				1600 1600 1600 1600 1600 1600 1600 1600 1600 1600 1600 1600 1600 1600 1600 1600 1600 1600
				1600 1600 1600 1600 1600 1600 1600 1600 1600 1600 1600 1600 1600 1600 1600 1600 1600 1600
				1600 1600 1600 1600 1600 1600 1600 1600 1600 1600 1600 1600 1600 1600 1600 1600 1600 1600
				1600 1600 1600 1600 1600 1600 1600 1600 1600 1600 1600 1600 1600 1600 1600 1600 1600 1600
				1600 1600 1600 1600 1600 1600 1600 1600 1600 1600 1600 1600 1600 1600 1600 1600 1600 1600
				2000 2000 2000>;

			PS_Config_Lmt_FW_Rawdata_N = <
				0 800 800 800 800 800 0 0 0 0 0 0 800 800 800 800 800 0
				800 800 800 800 800 800 800 800 800 800 800 800 800 800 800 800 800 800
				800 800 800 800 800 800 800 800 800 800 800 800 800 800 800 800 800 800
				800 800 800 800 800 800 800 800 800 800 800 800 800 800 800 800 800 800
				800 800 800 800 800 800 800 800 800 800 800 800 800 800 800 800 800 800
				800 800 800 800 800 800 800 800 800 800 800 800 800 800 800 800 800 800
				800 800 800 800 800 800 800 800 800 800 800 800 800 800 800 800 800 800
				800 800 800 800 800 800 800 800 800 800 800 800 800 800 800 800 800 800
				800 800 800 800 800 800 800 800 800 800 800 800 800 800 800 800 800 800
				800 800 800 800 800 800 800 800 800 800 800 800 800 800 800 800 800 800
				800 800 800 800 800 800 800 800 800 800 800 800 800 800 800 800 800 800
				800 800 800 800 800 800 800 800 800 800 800 800 800 800 800 800 800 800
				800 800 800 800 800 800 800 800 800 800 800 800 800 800 800 800 800 800
				800 800 800 800 800 800 800 800 800 800 800 800 800 800 800 800 800 800
				800 800 800 800 800 800 800 800 800 800 800 800 800 800 800 800 800 800
				800 800 800 800 800 800 800 800 800 800 800 800 800 800 800 800 800 800
				800 800 800 800 800 800 800 800 800 800 800 800 800 800 800 800 800 800
				800 800 800 800 800 800 800 800 800 800 800 800 800 800 800 800 800 800
				800 800 800 800 800 800 800 800 800 800 800 800 800 800 800 800 800 800
				800 800 800 800 800 800 800 800 800 800 800 800 800 800 800 800 800 800
				800 800 800 800 800 800 800 800 800 800 800 800 800 800 800 800 800 800
				800 800 800 800 800 800 800 800 800 800 800 800 800 800 800 800 800 800
				800 800 800 800 800 800 800 800 800 800 800 800 800 800 800 800 800 800
				800 800 800 800 800 800 800 800 800 800 800 800 800 800 800 800 800 800
				800 800 800 800 800 800 800 800 800 800 800 800 800 800 800 800 800 800
				800 800 800 800 800 800 800 800 800 800 800 800 800 800 800 800 800 800
				800 800 800 800 800 800 800 800 800 800 800 800 800 800 800 800 800 800
				800 800 800 800 800 800 800 800 800 800 800 800 800 800 800 800 800 800
				800 800 800 800 800 800 800 800 800 800 800 800 800 800 800 800 800 800
				800 800 800 800 800 800 800 800 800 800 800 800 800 800 800 800 800 800
				800 800 800 800 800 800 800 800 800 800 800 800 800 800 800 800 800 800
				800 800 800 800 800 800 800 800 800 800 800 800 800 800 800 800 800 800
				700 700 700>;

			PS_Config_Lmt_FW_CC_P = <
				140 140 140 140 140 140 140 140 140 140 140 140 140 140 140 140 140 140
				140 140 140 140 140 140 140 140 140 140 140 140 140 140 140 140 140 140
				140 140 140 140 140 140 140 140 140 140 140 140 140 140 140 140 140 140
				140 140 140 140 140 140 140 140 140 140 140 140 140 140 140 140 140 140
				140 140 140 140 140 140 140 140 140 140 140 140 140 140 140 140 140 140
				140 140 140 140 140 140 140 140 140 140 140 140 140 140 140 140 140 140
				140 140 140 140 140 140 140 140 140 140 140 140 140 140 140 140 140 140
				140 140 140 140 140 140 140 140 140 140 140 140 140 140 140 140 140 140
				140 140 140 140 140 140 140 140 140 140 140 140 140 140 140 140 140 140
				140 140 140 140 140 140 140 140 140 140 140 140 140 140 140 140 140 140
				140 140 140 140 140 140 140 140 140 140 140 140 140 140 140 140 140 140
				140 140 140 140 140 140 140 140 140 140 140 140 140 140 140 140 140 140
				140 140 140 140 140 140 140 140 140 140 140 140 140 140 140 140 140 140
				140 140 140 140 140 140 140 140 140 140 140 140 140 140 140 140 140 140
				140 140 140 140 140 140 140 140 140 140 140 140 140 140 140 140 140 140
				140 140 140 140 140 140 140 140 140 140 140 140 140 140 140 140 140 140
				140 140 140 140 140 140 140 140 140 140 140 140 140 140 140 140 140 140
				140 140 140 140 140 140 140 140 140 140 140 140 140 140 140 140 140 140
				140 140 140 140 140 140 140 140 140 140 140 140 140 140 140 140 140 140
				140 140 140 140 140 140 140 140 140 140 140 140 140 140 140 140 140 140
				140 140 140 140 140 140 140 140 140 140 140 140 140 140 140 140 140 140
				140 140 140 140 140 140 140 140 140 140 140 140 140 140 140 140 140 140
				140 140 140 140 140 140 140 140 140 140 140 140 140 140 140 140 140 140
				140 140 140 140 140 140 140 140 140 140 140 140 140 140 140 140 140 140
				140 140 140 140 140 140 140 140 140 140 140 140 140 140 140 140 140 140
				140 140 140 140 140 140 140 140 140 140 140 140 140 140 140 140 140 140
				140 140 140 140 140 140 140 140 140 140 140 140 140 140 140 140 140 140
				140 140 140 140 140 140 140 140 140 140 140 140 140 140 140 140 140 140
				140 140 140 140 140 140 140 140 140 140 140 140 140 140 140 140 140 140
				140 140 140 140 140 140 140 140 140 140 140 140 140 140 140 140 140 140
				140 140 140 140 140 140 140 140 140 140 140 140 140 140 140 140 140 140
				140 140 140 140 140 140 140 140 140 140 140 140 140 140 140 140 140 140
				160 160 160>;

			PS_Config_Lmt_FW_CC_N = <
				65 65 65 65 65 65 65 65 65 65 65 65 65 65 65 65 65 65
				65 65 65 65 65 65 65 65 65 65 65 65 65 65 65 65 65 65
				65 65 65 65 65 65 65 65 65 65 65 65 65 65 65 65 65 65
				65 65 65 65 65 65 65 65 65 65 65 65 65 65 65 65 65 65
				65 65 65 65 65 65 65 65 65 65 65 65 65 65 65 65 65 65
				65 65 65 65 65 65 65 65 65 65 65 65 65 65 65 65 65 65
				65 65 65 65 65 65 65 65 65 65 65 65 65 65 65 65 65 65
				65 65 65 65 65 65 65 65 65 65 65 65 65 65 65 65 65 65
				65 65 65 65 65 65 65 65 65 65 65 65 65 65 65 65 65 65
				65 65 65 65 65 65 65 65 65 65 65 65 65 65 65 65 65 65
				65 65 65 65 65 65 65 65 65 65 65 65 65 65 65 65 65 65
				65 65 65 65 65 65 65 65 65 65 65 65 65 65 65 65 65 65
				65 65 65 65 65 65 65 65 65 65 65 65 65 65 65 65 65 65
				65 65 65 65 65 65 65 65 65 65 65 65 65 65 65 65 65 65
				65 65 65 65 65 65 65 65 65 65 65 65 65 65 65 65 65 65
				65 65 65 65 65 65 65 65 65 65 65 65 65 65 65 65 65 65
				65 65 65 65 65 65 65 65 65 65 65 65 65 65 65 65 65 65
				65 65 65 65 65 65 65 65 65 65 65 65 65 65 65 65 65 65
				65 65 65 65 65 65 65 65 65 65 65 65 65 65 65 65 65 65
				65 65 65 65 65 65 65 65 65 65 65 65 65 65 65 65 65 65
				65 65 65 65 65 65 65 65 65 65 65 65 65 65 65 65 65 65
				65 65 65 65 65 65 65 65 65 65 65 65 65 65 65 65 65 65
				65 65 65 65 65 65 65 65 65 65 65 65 65 65 65 65 65 65
				65 65 65 65 65 65 65 65 65 65 65 65 65 65 65 65 65 65
				65 65 65 65 65 65 65 65 65 65 65 65 65 65 65 65 65 65
				65 65 65 65 65 65 65 65 65 65 65 65 65 65 65 65 65 65
				65 65 65 65 65 65 65 65 65 65 65 65 65 65 65 65 65 65
				65 65 65 65 65 65 65 65 65 65 65 65 65 65 65 65 65 65
				65 65 65 65 65 65 65 65 65 65 65 65 65 65 65 65 65 65
				65 65 65 65 65 65 65 65 65 65 65 65 65 65 65 65 65 65
				65 65 65 65 65 65 65 65 65 65 65 65 65 65 65 65 65 65
				65 65 65 65 65 65 65 65 65 65 65 65 65 65 65 65 65 65
				50 50 50>;

			PS_Config_Lmt_FW_CC_I_P = <
				25 25 25 25 25 25 25 25 25 25 25 25 25 25 25 25 25 25
				25 25 25 25 25 25 25 25 25 25 25 25 25 25 25 25 25 25
				25 25 25 25 25 25 25 25 25 25 25 25 25 25 25 25 25 25
				25 25 25 25 25 25 25 25 25 25 25 25 25 25 25 25 25 25
				25 25 25 25 25 25 25 25 25 25 25 25 25 25 25 25 25 25
				25 25 25 25 25 25 25 25 25 25 25 25 25 25 25 25 25 25
				25 25 25 25 25 25 25 25 25 25 25 25 25 25 25 25 25 25
				25 25 25 25 25 25 25 25 25 25 25 25 25 25 25 25 25 25
				25 25 25 25 25 25 25 25 25 25 25 25 25 25 25 25 25 25
				25 25 25 25 25 25 25 25 25 25 25 25 25 25 25 25 25 25
				25 25 25 25 25 25 25 25 25 25 25 25 25 25 25 25 25 25
				25 25 25 25 25 25 25 25 25 25 25 25 25 25 25 25 25 25
				25 25 25 25 25 25 25 25 25 25 25 25 25 25 25 25 25 25
				25 25 25 25 25 25 25 25 25 25 25 25 25 25 25 25 25 25
				25 25 25 25 25 25 25 25 25 25 25 25 25 25 25 25 25 25
				25 25 25 25 25 25 25 25 25 25 25 25 25 25 25 25 25 25
				25 25 25 25 25 25 25 25 25 25 25 25 25 25 25 25 25 25
				25 25 25 25 25 25 25 25 25 25 25 25 25 25 25 25 25 25
				25 25 25 25 25 25 25 25 25 25 25 25 25 25 25 25 25 25
				25 25 25 25 25 25 25 25 25 25 25 25 25 25 25 25 25 25
				25 25 25 25 25 25 25 25 25 25 25 25 25 25 25 25 25 25
				25 25 25 25 25 25 25 25 25 25 25 25 25 25 25 25 25 25
				25 25 25 25 25 25 25 25 25 25 25 25 25 25 25 25 25 25
				25 25 25 25 25 25 25 25 25 25 25 25 25 25 25 25 25 25
				25 25 25 25 25 25 25 25 25 25 25 25 25 25 25 25 25 25
				25 25 25 25 25 25 25 25 25 25 25 25 25 25 25 25 25 25
				25 25 25 25 25 25 25 25 25 25 25 25 25 25 25 25 25 25
				25 25 25 25 25 25 25 25 25 25 25 25 25 25 25 25 25 25
				25 25 25 25 25 25 25 25 25 25 25 25 25 25 25 25 25 25
				25 25 25 25 25 25 25 25 25 25 25 25 25 25 25 25 25 25
				25 25 25 25 25 25 25 25 25 25 25 25 25 25 25 25 25 25
				25 25 25 25 25 25 25 25 25 25 25 25 25 25 25 25 25 25
				25 25 25>;

			PS_Config_Lmt_FW_CC_I_N = <
				0 0 0 0 0 0 0 0 0 0 0 0 0 0 0 0 0 0
				0 0 0 0 0 0 0 0 0 0 0 0 0 0 0 0 0 0
				0 0 0 0 0 0 0 0 0 0 0 0 0 0 0 0 0 0
				0 0 0 0 0 0 0 0 0 0 0 0 0 0 0 0 0 0
				0 0 0 0 0 0 0 0 0 0 0 0 0 0 0 0 0 0
				0 0 0 0 0 0 0 0 0 0 0 0 0 0 0 0 0 0
				0 0 0 0 0 0 0 0 0 0 0 0 0 0 0 0 0 0
				0 0 0 0 0 0 0 0 0 0 0 0 0 0 0 0 0 0
				0 0 0 0 0 0 0 0 0 0 0 0 0 0 0 0 0 0
				0 0 0 0 0 0 0 0 0 0 0 0 0 0 0 0 0 0
				0 0 0 0 0 0 0 0 0 0 0 0 0 0 0 0 0 0
				0 0 0 0 0 0 0 0 0 0 0 0 0 0 0 0 0 0
				0 0 0 0 0 0 0 0 0 0 0 0 0 0 0 0 0 0
				0 0 0 0 0 0 0 0 0 0 0 0 0 0 0 0 0 0
				0 0 0 0 0 0 0 0 0 0 0 0 0 0 0 0 0 0
				0 0 0 0 0 0 0 0 0 0 0 0 0 0 0 0 0 0
				0 0 0 0 0 0 0 0 0 0 0 0 0 0 0 0 0 0
				0 0 0 0 0 0 0 0 0 0 0 0 0 0 0 0 0 0
				0 0 0 0 0 0 0 0 0 0 0 0 0 0 0 0 0 0
				0 0 0 0 0 0 0 0 0 0 0 0 0 0 0 0 0 0
				0 0 0 0 0 0 0 0 0 0 0 0 0 0 0 0 0 0
				0 0 0 0 0 0 0 0 0 0 0 0 0 0 0 0 0 0
				0 0 0 0 0 0 0 0 0 0 0 0 0 0 0 0 0 0
				0 0 0 0 0 0 0 0 0 0 0 0 0 0 0 0 0 0
				0 0 0 0 0 0 0 0 0 0 0 0 0 0 0 0 0 0
				0 0 0 0 0 0 0 0 0 0 0 0 0 0 0 0 0 0
				0 0 0 0 0 0 0 0 0 0 0 0 0 0 0 0 0 0
				0 0 0 0 0 0 0 0 0 0 0 0 0 0 0 0 0 0
				0 0 0 0 0 0 0 0 0 0 0 0 0 0 0 0 0 0
				0 0 0 0 0 0 0 0 0 0 0 0 0 0 0 0 0 0
				0 0 0 0 0 0 0 0 0 0 0 0 0 0 0 0 0 0
				0 0 0 0 0 0 0 0 0 0 0 0 0 0 0 0 0 0
				0 0 0>;

			PS_Config_Lmt_FW_CC_Q_P = <
				25 25 25 25 25 25 25 25 25 25 25 25 25 25 25 25 25 25
				25 25 25 25 25 25 25 25 25 25 25 25 25 25 25 25 25 25
				25 25 25 25 25 25 25 25 25 25 25 25 25 25 25 25 25 25
				25 25 25 25 25 25 25 25 25 25 25 25 25 25 25 25 25 25
				25 25 25 25 25 25 25 25 25 25 25 25 25 25 25 25 25 25
				25 25 25 25 25 25 25 25 25 25 25 25 25 25 25 25 25 25
				25 25 25 25 25 25 25 25 25 25 25 25 25 25 25 25 25 25
				25 25 25 25 25 25 25 25 25 25 25 25 25 25 25 25 25 25
				25 25 25 25 25 25 25 25 25 25 25 25 25 25 25 25 25 25
				25 25 25 25 25 25 25 25 25 25 25 25 25 25 25 25 25 25
				25 25 25 25 25 25 25 25 25 25 25 25 25 25 25 25 25 25
				25 25 25 25 25 25 25 25 25 25 25 25 25 25 25 25 25 25
				25 25 25 25 25 25 25 25 25 25 25 25 25 25 25 25 25 25
				25 25 25 25 25 25 25 25 25 25 25 25 25 25 25 25 25 25
				25 25 25 25 25 25 25 25 25 25 25 25 25 25 25 25 25 25
				25 25 25 25 25 25 25 25 25 25 25 25 25 25 25 25 25 25
				25 25 25 25 25 25 25 25 25 25 25 25 25 25 25 25 25 25
				25 25 25 25 25 25 25 25 25 25 25 25 25 25 25 25 25 25
				25 25 25 25 25 25 25 25 25 25 25 25 25 25 25 25 25 25
				25 25 25 25 25 25 25 25 25 25 25 25 25 25 25 25 25 25
				25 25 25 25 25 25 25 25 25 25 25 25 25 25 25 25 25 25
				25 25 25 25 25 25 25 25 25 25 25 25 25 25 25 25 25 25
				25 25 25 25 25 25 25 25 25 25 25 25 25 25 25 25 25 25
				25 25 25 25 25 25 25 25 25 25 25 25 25 25 25 25 25 25
				25 25 25 25 25 25 25 25 25 25 25 25 25 25 25 25 25 25
				25 25 25 25 25 25 25 25 25 25 25 25 25 25 25 25 25 25
				25 25 25 25 25 25 25 25 25 25 25 25 25 25 25 25 25 25
				25 25 25 25 25 25 25 25 25 25 25 25 25 25 25 25 25 25
				25 25 25 25 25 25 25 25 25 25 25 25 25 25 25 25 25 25
				25 25 25 25 25 25 25 25 25 25 25 25 25 25 25 25 25 25
				25 25 25 25 25 25 25 25 25 25 25 25 25 25 25 25 25 25
				25 25 25 25 25 25 25 25 25 25 25 25 25 25 25 25 25 25
				25 25 25>;

			PS_Config_Lmt_FW_CC_Q_N = <
				0 0 0 0 0 0 0 0 0 0 0 0 0 0 0 0 0 0
				0 0 0 0 0 0 0 0 0 0 0 0 0 0 0 0 0 0
				0 0 0 0 0 0 0 0 0 0 0 0 0 0 0 0 0 0
				0 0 0 0 0 0 0 0 0 0 0 0 0 0 0 0 0 0
				0 0 0 0 0 0 0 0 0 0 0 0 0 0 0 0 0 0
				0 0 0 0 0 0 0 0 0 0 0 0 0 0 0 0 0 0
				0 0 0 0 0 0 0 0 0 0 0 0 0 0 0 0 0 0
				0 0 0 0 0 0 0 0 0 0 0 0 0 0 0 0 0 0
				0 0 0 0 0 0 0 0 0 0 0 0 0 0 0 0 0 0
				0 0 0 0 0 0 0 0 0 0 0 0 0 0 0 0 0 0
				0 0 0 0 0 0 0 0 0 0 0 0 0 0 0 0 0 0
				0 0 0 0 0 0 0 0 0 0 0 0 0 0 0 0 0 0
				0 0 0 0 0 0 0 0 0 0 0 0 0 0 0 0 0 0
				0 0 0 0 0 0 0 0 0 0 0 0 0 0 0 0 0 0
				0 0 0 0 0 0 0 0 0 0 0 0 0 0 0 0 0 0
				0 0 0 0 0 0 0 0 0 0 0 0 0 0 0 0 0 0
				0 0 0 0 0 0 0 0 0 0 0 0 0 0 0 0 0 0
				0 0 0 0 0 0 0 0 0 0 0 0 0 0 0 0 0 0
				0 0 0 0 0 0 0 0 0 0 0 0 0 0 0 0 0 0
				0 0 0 0 0 0 0 0 0 0 0 0 0 0 0 0 0 0
				0 0 0 0 0 0 0 0 0 0 0 0 0 0 0 0 0 0
				0 0 0 0 0 0 0 0 0 0 0 0 0 0 0 0 0 0
				0 0 0 0 0 0 0 0 0 0 0 0 0 0 0 0 0 0
				0 0 0 0 0 0 0 0 0 0 0 0 0 0 0 0 0 0
				0 0 0 0 0 0 0 0 0 0 0 0 0 0 0 0 0 0
				0 0 0 0 0 0 0 0 0 0 0 0 0 0 0 0 0 0
				0 0 0 0 0 0 0 0 0 0 0 0 0 0 0 0 0 0
				0 0 0 0 0 0 0 0 0 0 0 0 0 0 0 0 0 0
				0 0 0 0 0 0 0 0 0 0 0 0 0 0 0 0 0 0
				0 0 0 0 0 0 0 0 0 0 0 0 0 0 0 0 0 0
				0 0 0 0 0 0 0 0 0 0 0 0 0 0 0 0 0 0
				0 0 0 0 0 0 0 0 0 0 0 0 0 0 0 0 0 0
				0 0 0>;

			PS_Config_Lmt_FW_Diff_P = <
				60 60 60 60 60 60 60 60 60 60 60 60 60 60 60 60 60 60
				60 60 60 60 60 60 60 60 60 60 60 60 60 60 60 60 60 60
				60 60 60 60 60 60 60 60 60 60 60 60 60 60 60 60 60 60
				60 60 60 60 60 60 60 60 60 60 60 60 60 60 60 60 60 60
				60 60 60 60 60 60 60 60 60 60 60 60 60 60 60 60 60 60
				60 60 60 60 60 60 60 60 60 60 60 60 60 60 60 60 60 60
				60 60 60 60 60 60 60 60 60 60 60 60 60 60 60 60 60 60
				60 60 60 60 60 60 60 60 60 60 60 60 60 60 60 60 60 60
				60 60 60 60 60 60 60 60 60 60 60 60 60 60 60 60 60 60
				60 60 60 60 60 60 60 60 60 60 60 60 60 60 60 60 60 60
				60 60 60 60 60 60 60 60 60 60 60 60 60 60 60 60 60 60
				60 60 60 60 60 60 60 60 60 60 60 60 60 60 60 60 60 60
				60 60 60 60 60 60 60 60 60 60 60 60 60 60 60 60 60 60
				60 60 60 60 60 60 60 60 60 60 60 60 60 60 60 60 60 60
				60 60 60 60 60 60 60 60 60 60 60 60 60 60 60 60 60 60
				60 60 60 60 60 60 60 60 60 60 60 60 60 60 60 60 60 60
				60 60 60 60 60 60 60 60 60 60 60 60 60 60 60 60 60 60
				60 60 60 60 60 60 60 60 60 60 60 60 60 60 60 60 60 60
				60 60 60 60 60 60 60 60 60 60 60 60 60 60 60 60 60 60
				60 60 60 60 60 60 60 60 60 60 60 60 60 60 60 60 60 60
				60 60 60 60 60 60 60 60 60 60 60 60 60 60 60 60 60 60
				60 60 60 60 60 60 60 60 60 60 60 60 60 60 60 60 60 60
				60 60 60 60 60 60 60 60 60 60 60 60 60 60 60 60 60 60
				60 60 60 60 60 60 60 60 60 60 60 60 60 60 60 60 60 60
				60 60 60 60 60 60 60 60 60 60 60 60 60 60 60 60 60 60
				60 60 60 60 60 60 60 60 60 60 60 60 60 60 60 60 60 60
				60 60 60 60 60 60 60 60 60 60 60 60 60 60 60 60 60 60
				60 60 60 60 60 60 60 60 60 60 60 60 60 60 60 60 60 60
				60 60 60 60 60 60 60 60 60 60 60 60 60 60 60 60 60 60
				60 60 60 60 60 60 60 60 60 60 60 60 60 60 60 60 60 60
				60 60 60 60 60 60 60 60 60 60 60 60 60 60 60 60 60 60
				60 60 60 60 60 60 60 60 60 60 60 60 60 60 60 60 60 60
				80 80 80>;

			PS_Config_Lmt_FW_Diff_N = <
				(-70) (-70) (-70) (-70) (-70) (-70) (-70) (-70) (-70) (-70) (-70) (-70) (-70) (-70) (-70) (-70) (-70) (-70)
				(-70) (-70) (-70) (-70) (-70) (-70) (-70) (-70) (-70) (-70) (-70) (-70) (-70) (-70) (-70) (-70) (-70) (-70)
				(-70) (-70) (-70) (-70) (-70) (-70) (-70) (-70) (-70) (-70) (-70) (-70) (-70) (-70) (-70) (-70) (-70) (-70)
				(-70) (-70) (-70) (-70) (-70) (-70) (-70) (-70) (-70) (-70) (-70) (-70) (-70) (-70) (-70) (-70) (-70) (-70)
				(-70) (-70) (-70) (-70) (-70) (-70) (-70) (-70) (-70) (-70) (-70) (-70) (-70) (-70) (-70) (-70) (-70) (-70)
				(-70) (-70) (-70) (-70) (-70) (-70) (-70) (-70) (-70) (-70) (-70) (-70) (-70) (-70) (-70) (-70) (-70) (-70)
				(-70) (-70) (-70) (-70) (-70) (-70) (-70) (-70) (-70) (-70) (-70) (-70) (-70) (-70) (-70) (-70) (-70) (-70)
				(-70) (-70) (-70) (-70) (-70) (-70) (-70) (-70) (-70) (-70) (-70) (-70) (-70) (-70) (-70) (-70) (-70) (-70)
				(-70) (-70) (-70) (-70) (-70) (-70) (-70) (-70) (-70) (-70) (-70) (-70) (-70) (-70) (-70) (-70) (-70) (-70)
				(-70) (-70) (-70) (-70) (-70) (-70) (-70) (-70) (-70) (-70) (-70) (-70) (-70) (-70) (-70) (-70) (-70) (-70)
				(-70) (-70) (-70) (-70) (-70) (-70) (-70) (-70) (-70) (-70) (-70) (-70) (-70) (-70) (-70) (-70) (-70) (-70)
				(-70) (-70) (-70) (-70) (-70) (-70) (-70) (-70) (-70) (-70) (-70) (-70) (-70) (-70) (-70) (-70) (-70) (-70)
				(-70) (-70) (-70) (-70) (-70) (-70) (-70) (-70) (-70) (-70) (-70) (-70) (-70) (-70) (-70) (-70) (-70) (-70)
				(-70) (-70) (-70) (-70) (-70) (-70) (-70) (-70) (-70) (-70) (-70) (-70) (-70) (-70) (-70) (-70) (-70) (-70)
				(-70) (-70) (-70) (-70) (-70) (-70) (-70) (-70) (-70) (-70) (-70) (-70) (-70) (-70) (-70) (-70) (-70) (-70)
				(-70) (-70) (-70) (-70) (-70) (-70) (-70) (-70) (-70) (-70) (-70) (-70) (-70) (-70) (-70) (-70) (-70) (-70)
				(-70) (-70) (-70) (-70) (-70) (-70) (-70) (-70) (-70) (-70) (-70) (-70) (-70) (-70) (-70) (-70) (-70) (-70)
				(-70) (-70) (-70) (-70) (-70) (-70) (-70) (-70) (-70) (-70) (-70) (-70) (-70) (-70) (-70) (-70) (-70) (-70)
				(-70) (-70) (-70) (-70) (-70) (-70) (-70) (-70) (-70) (-70) (-70) (-70) (-70) (-70) (-70) (-70) (-70) (-70)
				(-70) (-70) (-70) (-70) (-70) (-70) (-70) (-70) (-70) (-70) (-70) (-70) (-70) (-70) (-70) (-70) (-70) (-70)
				(-70) (-70) (-70) (-70) (-70) (-70) (-70) (-70) (-70) (-70) (-70) (-70) (-70) (-70) (-70) (-70) (-70) (-70)
				(-70) (-70) (-70) (-70) (-70) (-70) (-70) (-70) (-70) (-70) (-70) (-70) (-70) (-70) (-70) (-70) (-70) (-70)
				(-70) (-70) (-70) (-70) (-70) (-70) (-70) (-70) (-70) (-70) (-70) (-70) (-70) (-70) (-70) (-70) (-70) (-70)
				(-70) (-70) (-70) (-70) (-70) (-70) (-70) (-70) (-70) (-70) (-70) (-70) (-70) (-70) (-70) (-70) (-70) (-70)
				(-70) (-70) (-70) (-70) (-70) (-70) (-70) (-70) (-70) (-70) (-70) (-70) (-70) (-70) (-70) (-70) (-70) (-70)
				(-70) (-70) (-70) (-70) (-70) (-70) (-70) (-70) (-70) (-70) (-70) (-70) (-70) (-70) (-70) (-70) (-70) (-70)
				(-70) (-70) (-70) (-70) (-70) (-70) (-70) (-70) (-70) (-70) (-70) (-70) (-70) (-70) (-70) (-70) (-70) (-70)
				(-70) (-70) (-70) (-70) (-70) (-70) (-70) (-70) (-70) (-70) (-70) (-70) (-70) (-70) (-70) (-70) (-70) (-70)
				(-70) (-70) (-70) (-70) (-70) (-70) (-70) (-70) (-70) (-70) (-70) (-70) (-70) (-70) (-70) (-70) (-70) (-70)
				(-70) (-70) (-70) (-70) (-70) (-70) (-70) (-70) (-70) (-70) (-70) (-70) (-70) (-70) (-70) (-70) (-70) (-70)
				(-70) (-70) (-70) (-70) (-70) (-70) (-70) (-70) (-70) (-70) (-70) (-70) (-70) (-70) (-70) (-70) (-70) (-70)
				(-70) (-70) (-70) (-70) (-70) (-70) (-70) (-70) (-70) (-70) (-70) (-70) (-70) (-70) (-70) (-70) (-70) (-70)
				(-90) (-90) (-90)>;

			PS_Config_Diff_Test_Frame = <50>;
		};
	};
};
